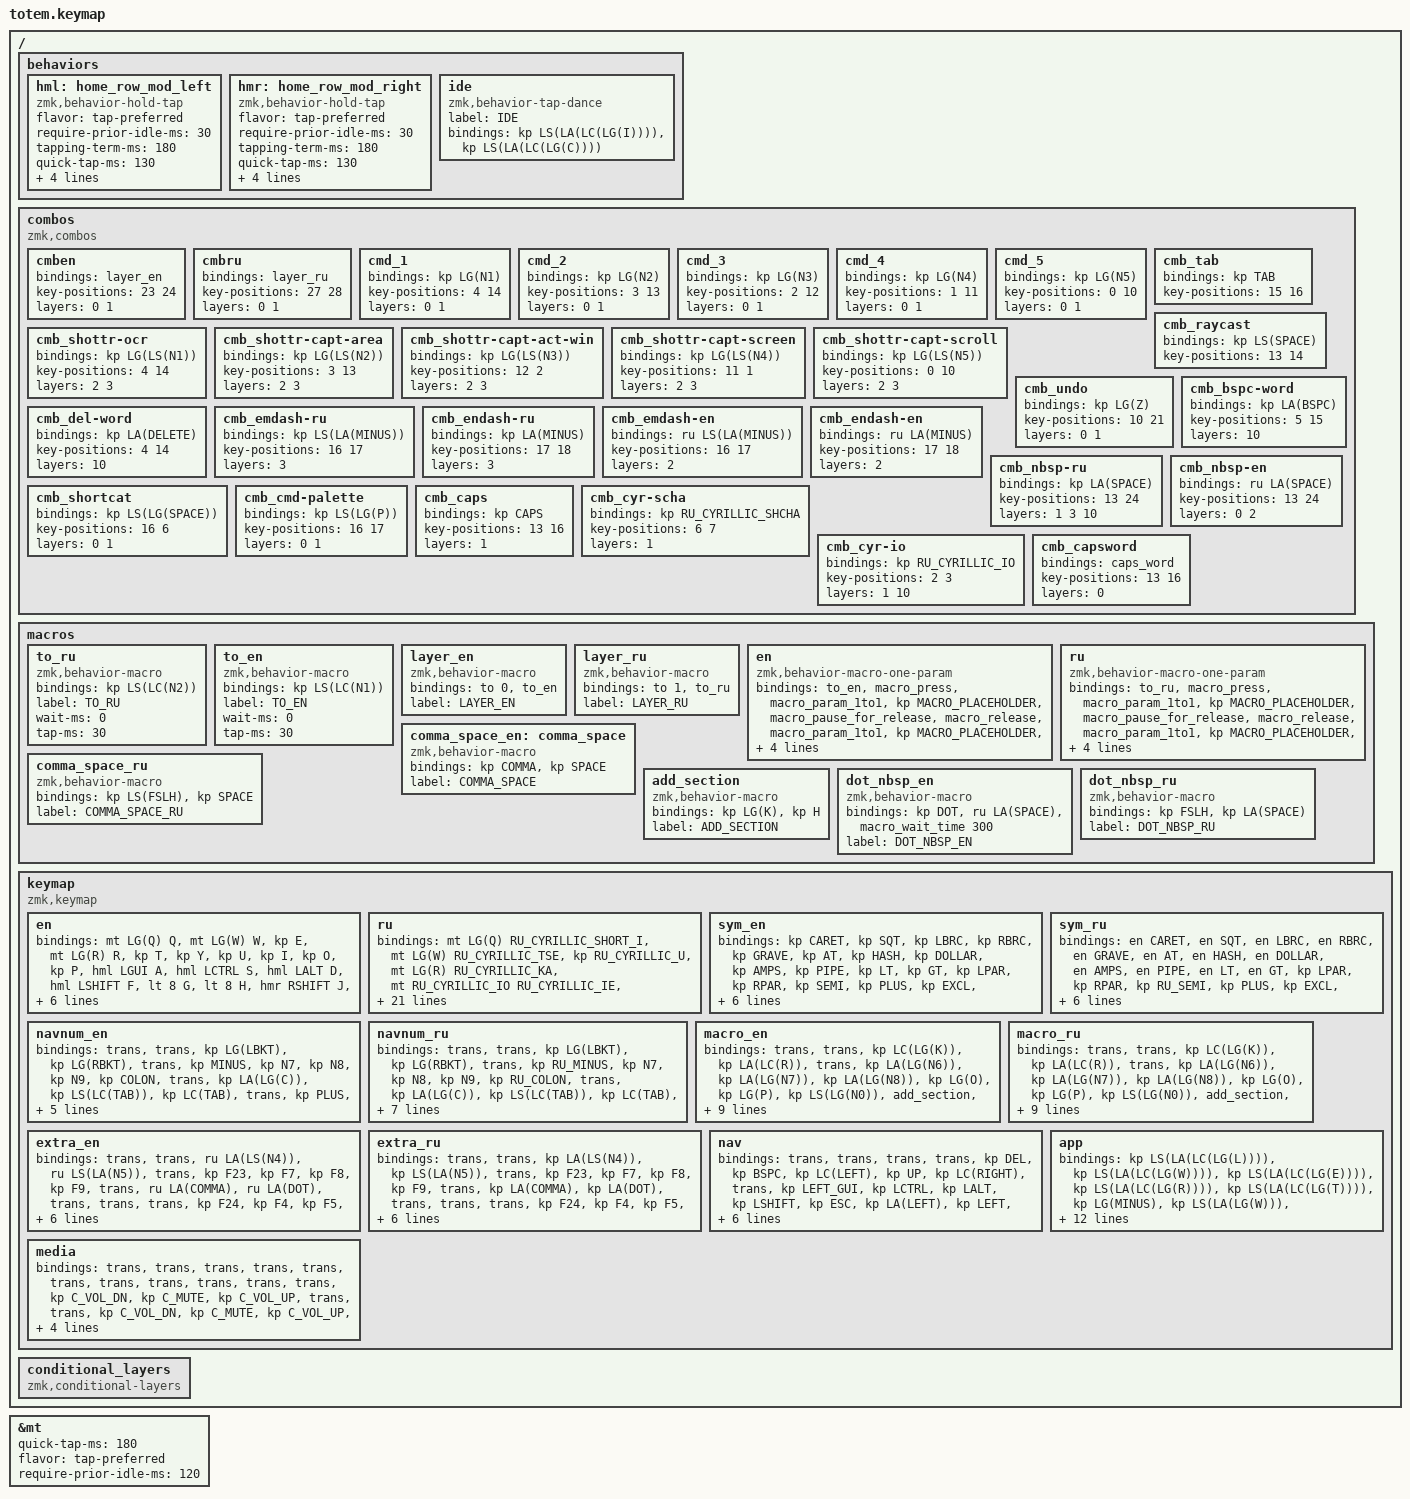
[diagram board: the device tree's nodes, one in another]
//
//                                                        ▀▀▀▀▀     ▀▀▀▀▀          ▀▀█▀▀
//                                                        ▄▀▀▀▄  ▄  ▄▀▀▀▄  ▄  ▄▀▀▀▄  █  ▄▀▀▀▄
//                                                        █   █  █  █   █  █  █   █  █  █   █
//                                                         ▀▀▀   █   ▀▀▀   █   ▀▀▀   ▀   ▀▀▀
//                                                               █      ▄▄▄█▄▄▄    █   █  
//                                                               ▀      █  █  █     █▄█
//                                                             ▀▀▀▀▀    █  █  █      ▀
//                                                                      ▀  ▀  ▀
//
// ▄▄▄▄▄▄▄▄▄▄▄▄▄▄▄▄▄▄▄▄▄▄▄▄▄▄▄▄▄▄▄▄▄▄▄▄▄▄▄▄▄▄▄▄▄▄▄▄▄▄▄▄▄▄▄▄▄▄▄▄▄▄▄▄▄▄▄▄▄▄▄▄▄▄▄▄▄▄▄▄▄▄▄▄▄▄▄▄▄▄▄▄▄▄▄▄▄▄▄▄▄▄▄▄▄▄▄▄▄▄▄▄▄▄▄▄▄▄▄▄▄▄▄▄▄▄▄▄▄▄▄▄▄▄▄▄▄▄▄▄▄▄▄▄▄▄▄▄▄

#define ZMK_POINTING_DEFAULT_SCRL_VAL 20

#include <behaviors.dtsi>
#include <dt-bindings/zmk/keys.h>
#include <dt-bindings/zmk/pointing.h>
#include "keys_ru.h"

&mt {
    quick-tap-ms = <180>;
    flavor = "tap-preferred";
    require-prior-idle-ms = <120>;
};

/ {
    behaviors {
        hml: home_row_mod_left {
            compatible = "zmk,behavior-hold-tap";
            #binding-cells = <2>;
            flavor = "tap-preferred";
            require-prior-idle-ms = <30>;
            tapping-term-ms = <180>;
            quick-tap-ms = <130>;
            bindings = <&kp>, <&kp>;

            hold-trigger-key-positions = <5 6 7 8 9 15 16 17 18 19 26 27 28 29 35 36 37 30 31>;
            hold-trigger-on-release;
        };

        hmr: home_row_mod_right {
            compatible = "zmk,behavior-hold-tap";
            #binding-cells = <2>;
            flavor = "tap-preferred";
            require-prior-idle-ms = <30>;
            tapping-term-ms = <180>;
            quick-tap-ms = <130>;
            bindings = <&kp>, <&kp>;

            hold-trigger-key-positions = <0 1 2 3 4 10 11 12 13 14 20 21 22 23 24 32 25 33 34>;
            hold-trigger-on-release;
        };

        ide: ide {
            compatible = "zmk,behavior-tap-dance";
            label = "IDE";
            #binding-cells = <0>;
            bindings = <&kp LS(LA(LC(LG(I))))>, <&kp LS(LA(LC(LG(C))))>;
        };
    };

    combos {
        compatible = "zmk,combos";

        cmben {
            bindings = <&layer_en>;
            key-positions = <23 24>;
            layers = <0 1>;
        };

        cmbru {
            bindings = <&layer_ru>;
            key-positions = <27 28>;
            layers = <0 1>;
        };

        cmd_1 {
            bindings = <&kp LG(N1)>;
            key-positions = <4 14>;
            layers = <0 1>;
        };

        cmd_2 {
            bindings = <&kp LG(N2)>;
            key-positions = <3 13>;
            layers = <0 1>;
        };

        cmd_3 {
            bindings = <&kp LG(N3)>;
            key-positions = <2 12>;
            layers = <0 1>;
        };

        cmd_4 {
            bindings = <&kp LG(N4)>;
            key-positions = <1 11>;
            layers = <0 1>;
        };

        cmd_5 {
            bindings = <&kp LG(N5)>;
            key-positions = <0 10>;
            layers = <0 1>;
        };

        cmb_tab {
            bindings = <&kp TAB>;
            key-positions = <15 16>;
        };

        cmb_raycast {
            bindings = <&kp LS(SPACE)>;
            key-positions = <13 14>;
        };

        cmb_shottr-ocr {
            bindings = <&kp LG(LS(N1))>;
            key-positions = <4 14>;
            layers = <2 3>;
        };

        cmb_shottr-capt-area {
            bindings = <&kp LG(LS(N2))>;
            key-positions = <3 13>;
            layers = <2 3>;
        };

        cmb_shottr-capt-act-win {
            bindings = <&kp LG(LS(N3))>;
            key-positions = <12 2>;
            layers = <2 3>;
        };

        cmb_shottr-capt-screen {
            bindings = <&kp LG(LS(N4))>;
            key-positions = <11 1>;
            layers = <2 3>;
        };

        cmb_shottr-capt-scroll {
            bindings = <&kp LG(LS(N5))>;
            key-positions = <0 10>;
            layers = <2 3>;
        };

        cmb_undo {
            bindings = <&kp LG(Z)>;
            key-positions = <10 21>;
            layers = <0 1>;
        };

        cmb_bspc-word {
            bindings = <&kp LA(BSPC)>;
            key-positions = <5 15>;
            layers = <10>;
        };

        cmb_del-word {
            bindings = <&kp LA(DELETE)>;
            key-positions = <4 14>;
            layers = <10>;
        };

        cmb_emdash-ru {
            bindings = <&kp LS(LA(MINUS))>;
            key-positions = <16 17>;
            layers = <3>;
        };

        cmb_endash-ru {
            bindings = <&kp LA(MINUS)>;
            key-positions = <17 18>;
            layers = <3>;
        };

        cmb_emdash-en {
            bindings = <&ru LS(LA(MINUS))>;
            key-positions = <16 17>;
            layers = <2>;
        };

        cmb_endash-en {
            bindings = <&ru LA(MINUS)>;
            key-positions = <17 18>;
            layers = <2>;
        };

        cmb_nbsp-ru {
            bindings = <&kp LA(SPACE)>;
            key-positions = <13 24>;
            layers = <1 3 10>;
        };

        cmb_nbsp-en {
            bindings = <&ru LA(SPACE)>;
            key-positions = <13 24>;
            layers = <0 2>;
        };

        cmb_shortcat {
            bindings = <&kp LS(LG(SPACE))>;
            key-positions = <16 6>;
            layers = <0 1>;
        };

        cmb_cmd-palette {
            bindings = <&kp LS(LG(P))>;
            key-positions = <16 17>;
            layers = <0 1>;
        };

        cmb_caps {
            bindings = <&kp CAPS>;
            key-positions = <13 16>;
            layers = <1>;
        };

        cmb_cyr-scha {
            bindings = <&kp RU_CYRILLIC_SHCHA>;
            key-positions = <6 7>;
            layers = <1>;
        };

        cmb_cyr-io {
            bindings = <&kp RU_CYRILLIC_IO>;
            key-positions = <2 3>;
            layers = <1 10>;
        };

        cmb_capsword {
            bindings = <&caps_word>;
            key-positions = <13 16>;
            layers = <0>;
        };
    };

    macros {
        to_ru: to_ru {
            compatible = "zmk,behavior-macro";
            #binding-cells = <0>;
            bindings = <&kp LS(LC(N2))>;
            label = "TO_RU";
            wait-ms = <0>;
            tap-ms = <30>;
        };

        to_en: to_en {
            compatible = "zmk,behavior-macro";
            #binding-cells = <0>;
            bindings = <&kp LS(LC(N1))>;
            label = "TO_EN";
            wait-ms = <0>;
            tap-ms = <30>;
        };

        layer_en: layer_en {
            compatible = "zmk,behavior-macro";
            #binding-cells = <0>;
            bindings = <&to 0 &to_en>;
            label = "LAYER_EN";
        };

        layer_ru: layer_ru {
            compatible = "zmk,behavior-macro";
            #binding-cells = <0>;
            bindings = <&to 1 &to_ru>;
            label = "LAYER_RU";
        };

        en: en {
            compatible = "zmk,behavior-macro-one-param";
            #binding-cells = <1>;
            bindings =
                <&to_en>,
                <&macro_press>,
                <&macro_param_1to1 &kp MACRO_PLACEHOLDER>,
                <&macro_pause_for_release>,
                <&macro_release>,
                <&macro_param_1to1 &kp MACRO_PLACEHOLDER>,
                <&macro_tap>,
                <&to_ru>;

            label = "EN";
            wait-ms = <0>;
            tap-ms = <30>;
        };

        ru: ru {
            compatible = "zmk,behavior-macro-one-param";
            #binding-cells = <1>;
            bindings =
                <&to_ru>,
                <&macro_press>,
                <&macro_param_1to1 &kp MACRO_PLACEHOLDER>,
                <&macro_pause_for_release>,
                <&macro_release>,
                <&macro_param_1to1 &kp MACRO_PLACEHOLDER>,
                <&macro_tap>,
                <&to_en>;

            label = "RU";
            wait-ms = <0>;
            tap-ms = <30>;
        };

        comma_space_en: comma_space {
            compatible = "zmk,behavior-macro";
            #binding-cells = <0>;
            bindings = <&kp COMMA &kp SPACE>;
            label = "COMMA_SPACE";
        };

        comma_space_ru: comma_space_ru {
            compatible = "zmk,behavior-macro";
            #binding-cells = <0>;
            bindings = <&kp LS(FSLH) &kp SPACE>;
            label = "COMMA_SPACE_RU";
        };

        add_section: add_section {
            compatible = "zmk,behavior-macro";
            #binding-cells = <0>;
            bindings = <&kp LG(K) &kp H>;
            label = "ADD_SECTION";
        };

        dot_nbsp_en: dot_nbsp_en {
            compatible = "zmk,behavior-macro";
            #binding-cells = <0>;
            bindings = <&kp DOT &ru LA(SPACE)>, <&macro_wait_time 300>;

            label = "DOT_NBSP_EN";
        };

        dot_nbsp_ru: dot_nbsp_ru {
            compatible = "zmk,behavior-macro";
            #binding-cells = <0>;
            bindings = <&kp FSLH &kp LA(SPACE)>;
            label = "DOT_NBSP_RU";
        };
    };

    keymap {
        compatible = "zmk,keymap";

        en {
            bindings = <
         &mt LG(Q) Q  &mt LG(W) W   &kp E        &mt LG(R) R    &kp T          &kp Y         &kp U          &kp I        &kp O         &kp P
         &hml LGUI A  &hml LCTRL S  &hml LALT D  &hml LSHIFT F  &lt 8 G        &lt 8 H       &hmr RSHIFT J  &hmr RALT K  &hmr RCTRL L  &hmr RGUI SEMI
&kp TAB  &lt 4 Z      &mt LG(X) X   &mt LG(C) C  &mt LG(V) V    &kp B          &mt LG(N) N   &kp M          &none        &none         &none           &comma_space_en
                                    &mo 12       &lt 11 ENTER   &lt 2 SPACE    &lt 10 MINUS  &lt 6 ESC      &lt 12 TAB
            >;
        };

        ru {
            bindings = <
         &mt LG(Q) RU_CYRILLIC_SHORT_I  &mt LG(W) RU_CYRILLIC_TSE    &kp RU_CYRILLIC_U         &mt LG(R) RU_CYRILLIC_KA   &mt RU_CYRILLIC_IO RU_CYRILLIC_IE    &kp RU_CYRILLIC_EN        &kp RU_CYRILLIC_GHE                              &kp RU_CYRILLIC_SHA       &kp RU_CYRILLIC_ZE         &kp RU_CYRILLIC_HA
         &hml LGUI RU_CYRILLIC_EF       &hml LCTRL RU_CYRILLIC_YERU  &hml LALT RU_CYRILLIC_VE  &hml LSHIFT RU_CYRILLIC_A  &lt 9 RU_CYRILLIC_PE                 &lt 9 RU_CYRILLIC_ER      &hmr RSHIFT RU_CYRILLIC_O                        &hmr RALT RU_CYRILLIC_EL  &hmr RCTRL RU_CYRILLIC_DE  &hmr RGUI RU_CYRILLIC_ZHE
&kp TAB  &lt 5 RU_CYRILLIC_YA           &mt LG(X) RU_CYRILLIC_CHE    &mt LG(C) RU_CYRILLIC_ES  &mt LG(V) RU_CYRILLIC_EM   &kp RU_CYRILLIC_I                    &mt LG(N) RU_CYRILLIC_TE  &mt RU_CYRILLIC_HARD_SIGN RU_CYRILLIC_SOFT_SIGN  &kp RU_CYRILLIC_BE        &kp RU_CYRILLIC_YU         &kp RU_CYRILLIC_E          &comma_space_ru
                                                                     &mo 12                    &lt 11 ENTER               &lt 3 SPACE                          &lt 10 MINUS              &lt 7 ESC                                        &lt 12 TAB
            >;
        };

        sym_en {
            bindings = <
       &kp CARET     &kp SQT           &kp LBRC        &kp RBRC   &kp GRAVE    &kp AT        &kp HASH  &kp DOLLAR  &kp AMPS   &kp PIPE
       &kp LT        &kp GT            &kp LPAR        &kp RPAR   &kp SEMI     &kp PLUS      &kp EXCL  &kp COLON   &kp QMARK  &kp EQUAL
&none  &ru LA(SEMI)  &ru LS(LA(SEMI))  &kp LBKT        &kp RBKT   &kp DQT      &kp ASTRK     &kp FSLH  &kp UNDER   &kp BSLH   &kp TILDE  &none
                                       &ru LS(LA(N8))  &ru LA(H)  &trans       &lt 10 COMMA  &kp DOT   &kp PRCNT
            >;
        };

        sym_ru {
            bindings = <
              &en CARET     &en SQT           &en LBRC        &en RBRC   &en GRAVE      &en AT           &en HASH     &en DOLLAR    &en AMPS         &en PIPE
              &en LT        &en GT            &kp LPAR        &kp RPAR   &kp RU_SEMI    &kp PLUS         &kp EXCL     &kp RU_COLON  &kp RU_QUESTION  &kp EQUAL
&dot_nbsp_ru  &kp LA(SEMI)  &kp LS(LA(SEMI))  &en LBKT        &en RBKT   &kp RU_DQT     &kp ASTRK        &kp RU_FSLH  &kp RU_UNDER  &kp RU_BSLH      &en TILDE  &none
                                              &ru LS(LA(N8))  &ru LA(H)  &trans         &lt 10 RU_COMMA  &kp RU_DOT   &kp PRCNT
            >;
        };

        navnum_en {
            bindings = <
        &trans  &trans                &kp LG(LBKT)     &kp LG(RBKT)   &trans    &kp MINUS     &kp N7   &kp N8     &kp N9  &kp COLON
        &trans  &kp LA(LG(C))         &kp LS(LC(TAB))  &kp LC(TAB)    &trans    &kp PLUS      &kp N4   &kp N5     &kp N6  &kp N0
&trans  &trans  &kp LS(LA(LG(RBKT)))  &kp LC(LG(W))    &kp LC(LG(E))  &trans    &kp ASTRK     &kp N1   &kp N2     &kp N3  &kp FSLH   &comma_space_en
                                      &trans           &trans         &kp N0    &lt 10 COMMA  &kp DOT  &kp PRCNT
            >;
        };

        navnum_ru {
            bindings = <
        &trans  &trans                &kp LG(LBKT)     &kp LG(RBKT)   &trans    &kp RU_MINUS     &kp N7      &kp N8        &kp N9  &kp RU_COLON
        &trans  &kp LA(LG(C))         &kp LS(LC(TAB))  &kp LC(TAB)    &trans    &kp PLUS         &kp N4      &kp N5        &kp N6  &kp N0
&trans  &trans  &kp LS(LA(LG(RBKT)))  &kp LC(LG(W))    &kp LC(LG(E))  &trans    &kp RU_ASTRK     &kp N1      &kp N2        &kp N3  &kp RU_FSLH   &comma_space_ru
                                      &trans           &trans         &kp N0    &lt 10 RU_COMMA  &kp RU_DOT  &kp RU_PRCNT
            >;
        };

        macro_en {
            bindings = <
        &trans          &trans        &kp LC(LG(K))  &kp LA(LC(R))  &trans       &kp LA(LG(N6))     &kp LA(LG(N7))  &kp LA(LG(N8))     &kp LG(O)           &kp LG(P)
        &kp LS(LG(N0))  &add_section  &kp LA(MINUS)  &kp LS(LG(M))  &trans       &kp LA(LC(LG(M)))  &kp LS(F3)      &kp LA(LC(LG(Z)))  &kp LA(LC(LG(N2)))  &kp LA(LC(LG(S)))
&trans  &trans          &trans        &kp LS(LG(C))  &kp LA(LC(V))  &trans       &trans             &kp LA(LC(A))   &kp LA(LC(R))      &kp LG(N8)          &kp LA(LC(LG(G)))  &trans
                                      &trans         &kp LG(ENTER)  &kp K_APP    &trans             &trans          &kp LC(LG(C))
            >;
        };

        macro_ru {
            bindings = <
        &trans          &trans        &kp LC(LG(K))  &kp LA(LC(R))  &trans       &kp LA(LG(N6))     &kp LA(LG(N7))  &kp LA(LG(N8))     &kp LG(O)           &kp LG(P)
        &kp LS(LG(N0))  &add_section  &kp LA(MINUS)  &kp LS(LG(M))  &trans       &kp LA(LC(LG(M)))  &kp LS(F3)      &en LA(LC(LG(Z)))  &en LA(LC(LG(N2)))  &en LA(LC(LG(S)))
&trans  &trans          &trans        &kp LS(LG(C))  &kp LA(LC(V))  &trans       &trans             &en LA(LC(A))   &en LA(LC(R))      &kp LG(N8)          &en LA(LC(LG(G)))  &trans
                                      &trans         &kp LG(ENTER)  &kp K_APP    &trans             &trans          &kp LC(LG(C))
            >;
        };

        extra_en {
            bindings = <
        &trans         &trans       &ru LA(LS(N4))  &ru LS(LA(N5))          &trans                    &kp F23  &kp F7     &kp F8  &kp F9  &trans
        &ru LA(COMMA)  &ru LA(DOT)  &trans          &trans                  &trans                    &kp F24  &kp F4     &kp F5  &kp F6  &trans
&trans  &trans         &trans       &ru LA(N5)      &trans                  &trans                    &trans   &kp F1     &kp F2  &kp F3  &trans  &trans
                                    &trans          &kp LS(LA(LC(LG(N2))))  &kp LS(LA(LC(LG(N1))))    &trans   &ru LA(G)  &trans
            >;
        };

        extra_ru {
            bindings = <
        &trans         &trans       &kp LA(LS(N4))  &kp LS(LA(N5))          &trans                    &kp F23  &kp F7     &kp F8  &kp F9  &trans
        &kp LA(COMMA)  &kp LA(DOT)  &trans          &trans                  &trans                    &kp F24  &kp F4     &kp F5  &kp F6  &trans
&trans  &trans         &trans       &kp LA(N5)      &trans                  &trans                    &trans   &kp F1     &kp F2  &kp F3  &trans  &trans
                                    &trans          &kp LS(LA(LC(LG(N2))))  &kp LS(LA(LC(LG(N1))))    &trans   &kp LA(G)  &trans
            >;
        };

        nav {
            bindings = <
        &trans        &trans     &trans     &trans      &kp DEL                  &kp BSPC      &kp LC(LEFT)    &kp UP        &kp LC(RIGHT)  &trans
        &kp LEFT_GUI  &kp LCTRL  &kp LALT   &kp LSHIFT  &kp ESC                  &kp LA(LEFT)  &kp LEFT        &kp DOWN      &kp RIGHT      &kp LA(RIGHT)
&trans  &trans        &trans     &mkp RCLK  &mkp LCLK   &kp LS(LA(LC(LG(P))))    &kp LG(LEFT)  &msc SCRL_DOWN  &msc SCRL_UP  &kp LA(F20)    &kp LG(RIGHT)  &trans
                                 &trans     &kp ENTER   &kp SPACE                &none         &none           &trans
            >;
        };

        app {
            bindings = <
                       &kp LS(LA(LC(LG(L))))  &kp LS(LA(LC(LG(W))))  &kp LS(LA(LC(LG(E))))  &kp LS(LA(LC(LG(R))))  &kp LS(LA(LC(LG(T))))    &kp LG(MINUS)  &kp LS(LA(LG(W)))  &kp LS(LA(LG(E)))  &kp LS(LA(LG(R)))  &trans
                       &kp LS(LA(LC(LG(Z))))  &kp LS(LA(LC(LG(D))))  &kp LS(LA(LC(LG(F))))  &kp LS(LA(LC(LG(B))))  &kp LS(LA(LC(LG(G))))    &kp LG(EQUAL)  &kp LS(LA(LG(S)))  &kp LS(LA(LG(D)))  &kp LS(LA(LG(F)))  &kp LS(LA(LG(G)))
&kp LS(LA(LC(LG(S))))  &kp LS(LA(LC(LG(N))))  &kp LS(LA(LC(LG(K))))  &kp LS(LA(LC(LG(A))))  &ide                   &kp LS(LA(LC(LG(M))))    &kp LG(N0)     &kp LS(LA(LG(X)))  &kp LS(LA(LG(C)))  &kp LS(LA(LG(V)))  &kp LS(LA(LG(A)))  &trans
                                                                     &trans                 &trans                 &trans                   &trans         &trans             &trans
            >;
        };

        media {
            bindings = <
        &trans  &trans        &trans            &trans        &trans    &trans  &trans        &trans      &trans        &trans
        &trans  &kp C_VOL_DN  &kp C_MUTE        &kp C_VOL_UP  &trans    &trans  &kp C_VOL_DN  &kp C_MUTE  &kp C_VOL_UP  &trans
&trans  &trans  &kp C_PREV    &kp C_PLAY_PAUSE  &kp C_NEXT    &trans    &trans  &kp C_PREV    &kp C_PP    &kp C_NEXT    &trans  &trans
                              &trans            &trans        &trans    &trans  &trans        &trans
            >;
        };
    };

    conditional_layers { compatible = "zmk,conditional-layers"; };
};
